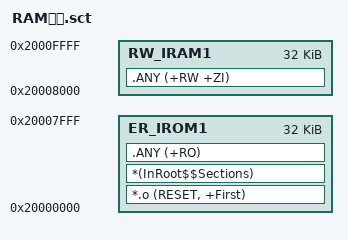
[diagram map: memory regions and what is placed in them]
;若RAM版本工程提示找不到sct文件，把本文件改名为“RAM版本.sct”复制至Output目录即可
; *************************************************************
; *** Scatter-Loading Description File generated by uVision ***
; *************************************************************

LR_IROM1 0x20000000 0x00008000  {    ; load region size_region
  ER_IROM1 0x20000000 0x00008000  {  ; load address = execution address
   *.o (RESET, +First)
   *(InRoot$$Sections)
   .ANY (+RO)
  }
  RW_IRAM1 0x20008000 0x00008000  {  ; RW data
   .ANY (+RW +ZI)
  }
}

